# MSPM0G511X register map
Vendor: Texas Instruments; File version: Revised: 2025-07-22 15:38:34
CPU: CM0 r0p1, little endian, MPU, no FPU, 3 interrupt priority bits
Registers are 32-bit, read-write, reset 0x0 unless marked. A register's access mark holds for its fields unless they carry their own. Offsets are from the block's base; [hi:lo] are bit positions; lines under a group give offsets from that group; {n}, {i} and the like mark numbered series; 'fields as' and 'values as' point back to an identical list.

## VREF — PERIPHERALREGION
Base 0x40030000
{0x800+0x18*i} VREF_GPRCM[{i}] (i=0..0) group
  0x00 VREF_PWREN — Power enable
    [0] ENABLE — Enable the power
      0=DISABLE (Disable Power); 1=ENABLE (Enable Power)
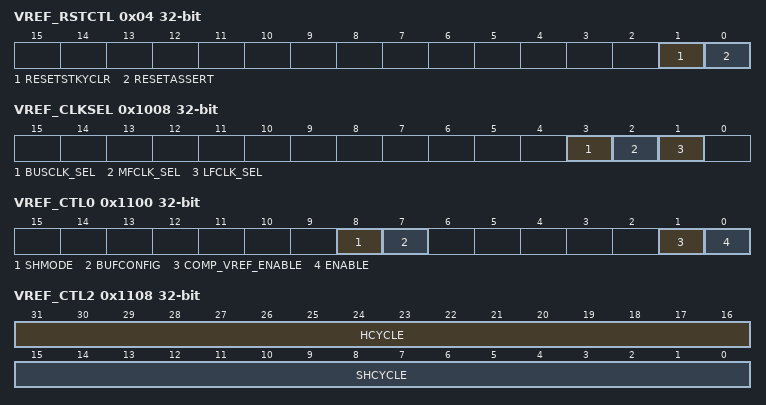
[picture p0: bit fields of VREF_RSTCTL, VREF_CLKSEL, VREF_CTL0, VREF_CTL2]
  0x04 VREF_RSTCTL wo — Reset Control
    [1] RESETSTKYCLR — Clear the RESETSTKY bit in the STAT register
      0=NOP (Writing 0 has no effect); 1=CLR (Clear reset sticky bit)
    [0] RESETASSERT — Assert reset to the peripheral
      0=NOP (Writing 0 has no effect); 1=ASSERT (Assert reset)
  0x14 VREF_STAT ro — Status Register
    [16] RESETSTKY — This bit indicates, if the peripheral was reset, since this bit was cleared by RESETSTKYCLR in the RSTCTL register
      0=NORES (The peripheral has not been reset since this bit was last cleared by RESETSTKYCLR in the RSTCTL register); 1=RESET (The peripheral was reset since the last bit clear)
0x1000 VREF_CLKDIV — Clock Divider
  [2:0] RATIO — Selects divide ratio of module clock to be used in sample and hold logic
0x1008 VREF_CLKSEL — Clock Selection
  [3] BUSCLK_SEL — Selects BUSCLK as clock source if enabled
  [2] MFCLK_SEL — Selects MFCLK as clock source if enabled
  [1] LFCLK_SEL — Selects LFCLK as clock source if enabled
0x1100 VREF_CTL0 — Control 0
  [8] SHMODE — This bit enable sample and hold mode
    0=DISABLE (Sample and hold mode is disable); 1=Enable (Sample and hold mode is enable)
  [7] BUFCONFIG — These bits configure output buffer.
    0=OUTPUT2P5V (Configure Output Buffer to 2.5v); 1=OUTPUT1P4V (Configure Output Buffer to 1.4v)
  [1] COMP_VREF_ENABLE — Comparator Vref Enable
    0=DISABLE (COMP VREF is disabled); 1=ENABLE (COMP VREF is enabled)
  [0] ENABLE — This bit enables the VREF module.
    0=DISABLE (VREF is disabled); 1=ENABLE (VREF is enabled)
0x1104 VREF_CTL1 — Control 1
  [0] READY ro — These bits defines status of VREF
    0=NOTRDY (VREF output is not ready); 1=RDY (VREF output is ready)
0x1108 VREF_CTL2 — Control 2
  [31:16] HCYCLE — Hold cycle count Total cycles of module clock for hold phase when VREF is working in sample and hold mode in STANDBY to save power. Please refer VREF section of datasheet for recommended values of sample and hold times.
  [15:0] SHCYCLE — Sample and Hold cycle count Total cycles of module clock for sample and hold phase when VREF is working in sample and hold mode in STANDBY to save power. This field should be greater than HCYCLE field. The difference between this field and HCYCLE gives the number of cycles of sample phase. Please refer VREF section of datasheet for recommended values of sample and hold times.

## CPUSS — CPUSSMMR
Base 0x40400000
0x10E0 CPUSS_EVT_MODE ro — Event Mode
  [1:0] INT_CFG — Event line mode select
    0=DISABLE (The interrupt or event line is disabled.); 1=SOFTWARE (Event handled by software. Software must clear the associated RIS flag.); 2=HARDWARE (Event handled by hardware. The hardware (another module) clears automatically the associated RIS flag.)
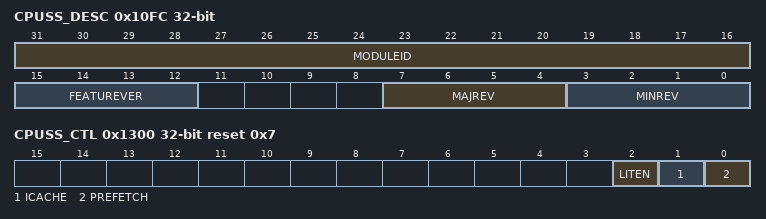
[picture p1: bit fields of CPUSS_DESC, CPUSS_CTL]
0x10FC CPUSS_DESC ro — Module Description
  [31:16] MODULEID — Module identification contains a unique peripheral identification number. The assignments are maintained in a central database for all of the platform modules to ensure uniqueness.
  [15:12] FEATUREVER — Feature Set for the module *instance*
  [7:4] MAJREV — Major rev of the IP
  [3:0] MINREV — Minor rev of the IP
{0x1100+0x2C*i} CPUSS_CPU_INT_GROUP0[{i}] (i=0..0) group
  0x00 CPUSS_CPU_INT_GROUP0_IIDX ro — Interrupt index
    [7:0] STAT — Interrupt index status
      0=NO_INTR (No pending interrupt); {v}=INT{v-1} (Interrupt {v-1}) (v=1..8)
  0x08 CPUSS_CPU_INT_GROUP0_IMASK ro reset 0xFF — Interrupt mask
    [7:0] INT — Masks the corresponding interrupt
      1=Interrupt 0; 2=Interrupt 1; 4=Interrupt 2; 8=Interrupt 3; 16=Interrupt 4; 32=Interrupt 5; 64=Interrupt 6; 128=Interrupt 7
  0x10 CPUSS_CPU_INT_GROUP0_RIS ro — Raw interrupt status
    [7:0] INT — Raw interrupt status for INT
      values as CPUSS_CPU_INT_GROUP0[0].CPUSS_CPU_INT_GROUP0_IMASK.INT
  0x18 CPUSS_CPU_INT_GROUP0_MIS ro — Masked interrupt status
    [7:0] INT — Masked interrupt status for INT0
      values as CPUSS_CPU_INT_GROUP0[0].CPUSS_CPU_INT_GROUP0_IMASK.INT
  0x20 CPUSS_CPU_INT_GROUP0_ISET wo — Interrupt set
    [7:0] INT — Sets INT in RIS register
      values as CPUSS_CPU_INT_GROUP0[0].CPUSS_CPU_INT_GROUP0_IMASK.INT
  0x28 CPUSS_CPU_INT_GROUP0_ICLR wo — Interrupt clear
    [7:0] INT — Clears INT in RIS register
      values as CPUSS_CPU_INT_GROUP0[0].CPUSS_CPU_INT_GROUP0_IMASK.INT
{0x1130+0x2C*i} CPUSS_CPU_INT_GROUP1[{i}] (i=0..0) group
  0x00 CPUSS_CPU_INT_GROUP1_IIDX ro — Interrupt index
    fields as CPUSS_CPU_INT_GROUP0[0].CPUSS_CPU_INT_GROUP0_IIDX
  0x08 CPUSS_CPU_INT_GROUP1_IMASK ro reset 0xFF — Interrupt mask
    fields as CPUSS_CPU_INT_GROUP0[0].CPUSS_CPU_INT_GROUP0_IMASK
  0x10 CPUSS_CPU_INT_GROUP1_RIS ro — Raw interrupt status
    fields as CPUSS_CPU_INT_GROUP0[0].CPUSS_CPU_INT_GROUP0_RIS
  0x18 CPUSS_CPU_INT_GROUP1_MIS ro — Masked interrupt status
    fields as CPUSS_CPU_INT_GROUP0[0].CPUSS_CPU_INT_GROUP0_MIS
  0x20 CPUSS_CPU_INT_GROUP1_ISET wo — Interrupt set
    fields as CPUSS_CPU_INT_GROUP0[0].CPUSS_CPU_INT_GROUP0_ISET
  0x28 CPUSS_CPU_INT_GROUP1_ICLR wo — Interrupt clear
    fields as CPUSS_CPU_INT_GROUP0[0].CPUSS_CPU_INT_GROUP0_ICLR
0x1300 CPUSS_CTL reset 0x7 — Prefetch/Cache control
  [2] LITEN — Literal caching and prefetch enable. This bit is a subset of ICACHE/PREFETCH bit i.e. literal caching or literal prefetching will only happen if ICACHE or PREFETCH bits have been set respectively When enabled, the cache and prefetcher structures inside CPUSS will cache and prefetch literals When disabled, the cache and prefetcher structures inside CPUSS will not cache and prefetch literals
    0=DISABLE (Literal caching disabled); 1=ENABLE (Literal caching enabled)
  [1] ICACHE — Used to enable/disable Instruction caching on flash access.
    0=DISABLE (Disable instruction caching.); 1=ENABLE (Enable instruction caching.)
  [0] PREFETCH — Used to enable/disable instruction prefetch to Flash.
    0=DISABLE (Disable instruction prefetch.); 1=ENABLE (Enable instruction prefetch.)
